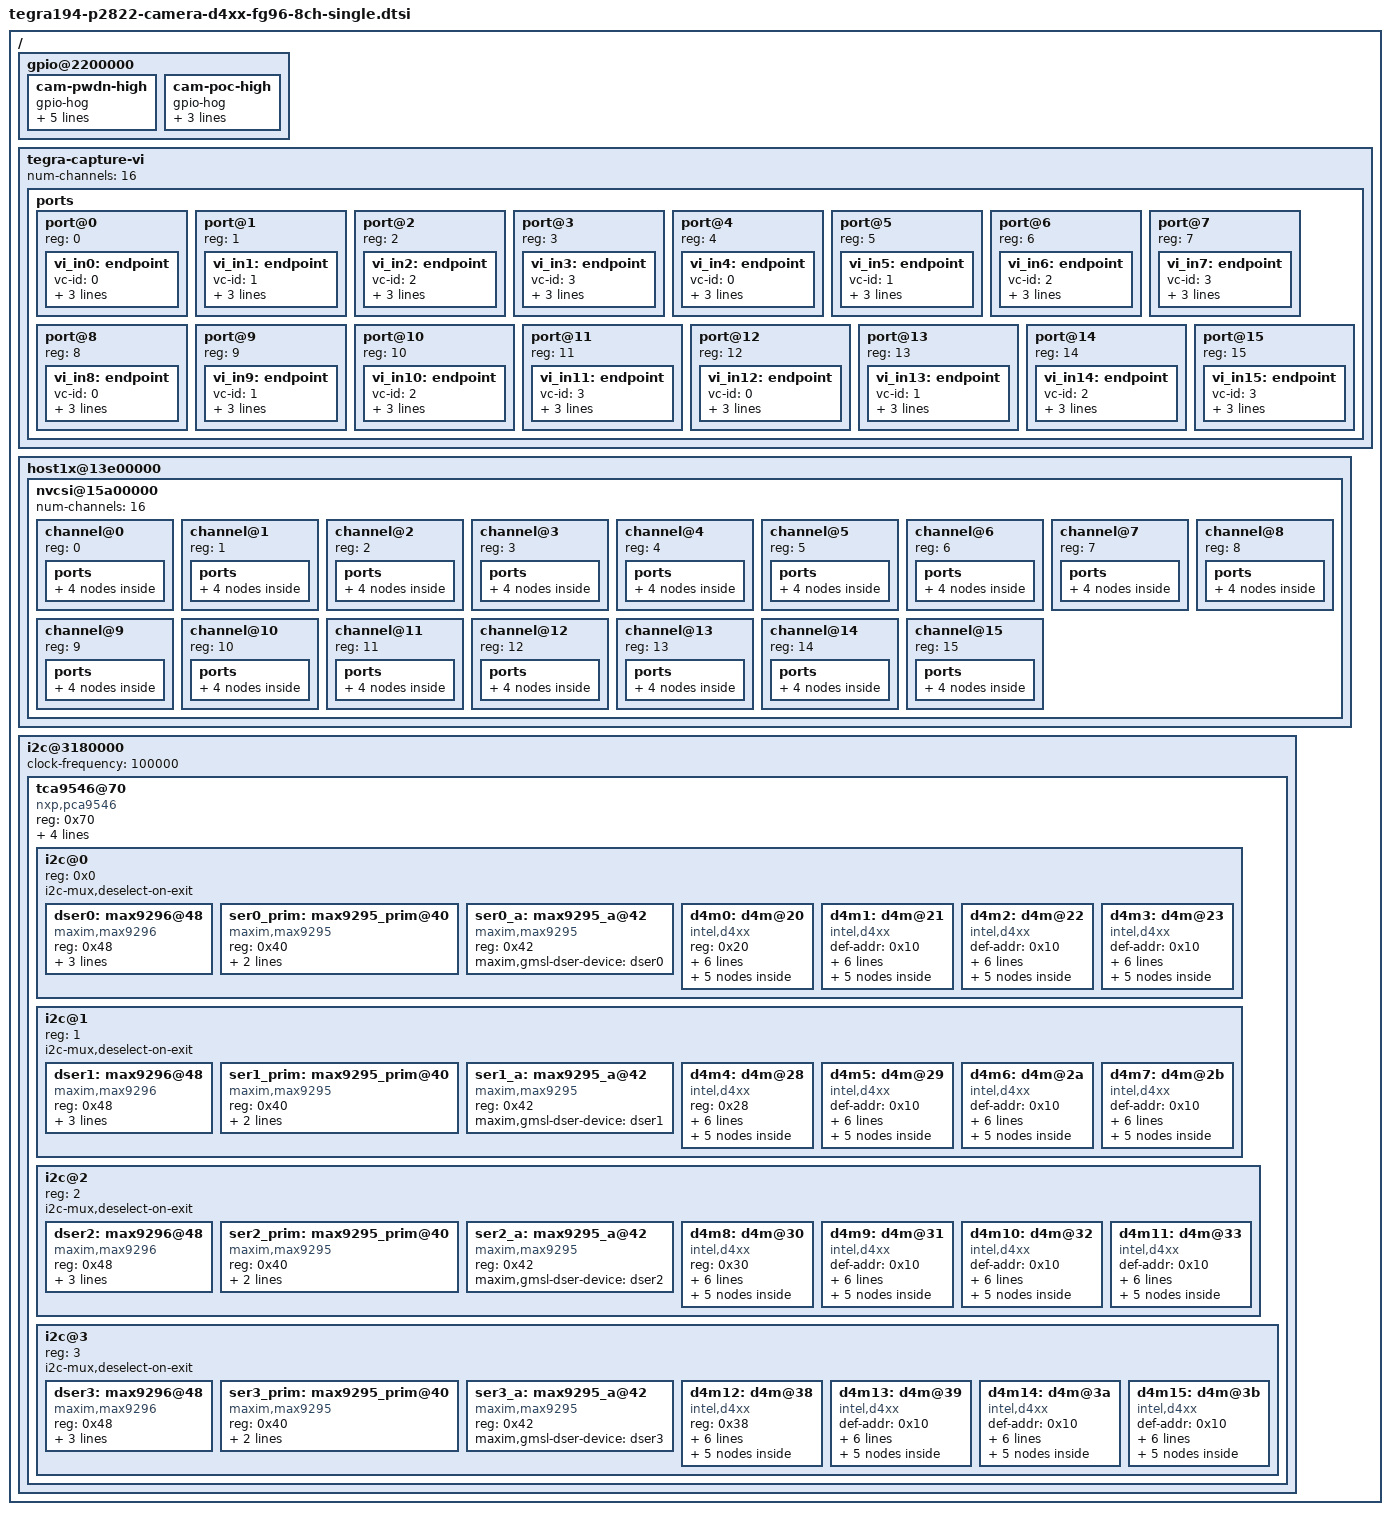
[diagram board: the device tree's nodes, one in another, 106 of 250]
// URL: https://fg96-8ch-doc.readthedocs.io/

#include "dt-bindings/clock/tegra194-clock.h"

#define CAM0_PWDN TEGRA194_MAIN_GPIO(H, 6)
#define CAM1_PWDN TEGRA194_MAIN_GPIO(H, 3)
#define CAM2_PWDN TEGRA194_MAIN_GPIO(T, 5)
#define CAM3_PWDN TEGRA194_MAIN_GPIO(T, 6)

#define CAM12V_POC TEGRA194_MAIN_GPIO(M, 5)

#define CAMERA_I2C_MUX_BUS(x) (0x1E + x)

// d4m addr 0x001cclss
// cc: max9296 index.  [0-3] for fg96
// l : a/b link index. [0-1] for a/b
// ss: stream index.   [0-3] for stream. 0: depth 1: color 2: ir 3: imu
// 4x max9296 - 4x d457
// [0x20-0x23][0x28-0x2b][0x30-0x33][0x38-0x3b]
// 4x max9296 - 8x d457
// [0x20-0x23][0x24-0x27]
// [0x28-0x2b][0x2c-0x2f]
// [0x30-0x33][0x34-0x37]
// [0x38-0x3b][0x3c-0x3f]

/ {
	gpio@2200000 {
		cam-pwdn-high {
			gpio-hog;
			output-high;
			gpios = <CAM0_PWDN 0 CAM1_PWDN 0
				 CAM2_PWDN 0 CAM3_PWDN 0>;
			label = "cam0-pwdn", "cam1-pwdn",
				"cam2-pwdn", "cam3-pwdn";
		};
		cam-poc-high {
			gpio-hog;
			output-high;
			gpios = <CAM12V_POC 0>;
			label = "cam12-poc";
		};
	};

	tegra-capture-vi {
		num-channels = <16>;

		ports {
			#address-cells = <1>;
			#size-cells = <0>;

			port@0 {
				reg = <0>;
				status = "okay";

				vi_in0: endpoint {
					status = "okay";
					vc-id = <0>;
					port-index = <0>;
					bus-width = <2>;
					remote-endpoint = <&csi_out0>;
				};
			};
			port@1 {
				reg = <1>;
				status = "okay";

				vi_in1: endpoint {
					status = "okay";
					vc-id = <1>;
					port-index = <0>;
					bus-width = <2>;
					remote-endpoint = <&csi_out1>;
				};
			};
			port@2 {
				reg = <2>;
				status = "okay";

				vi_in2: endpoint {
					status = "okay";
					vc-id = <2>;
					port-index = <0>;
					bus-width = <2>;
					remote-endpoint = <&csi_out2>;
				};
			};
			port@3 {
				reg = <3>;
				status = "okay";

				vi_in3: endpoint {
					status = "okay";
					vc-id = <3>;
					port-index = <0>;
					bus-width = <2>;
					remote-endpoint = <&csi_out3>;
				};
			};
			port@4 {
				reg = <4>;
				status = "okay";

				vi_in4: endpoint {
					status = "okay";
					vc-id = <0>;
					port-index = <2>;
					bus-width = <2>;
					remote-endpoint = <&csi_out4>;
				};
			};
			port@5 {
				reg = <5>;
				status = "okay";

				vi_in5: endpoint {
					status = "okay";
					vc-id = <1>;
					port-index = <2>;
					bus-width = <2>;
					remote-endpoint = <&csi_out5>;
				};
			};
			port@6 {
				reg = <6>;
				status = "okay";

				vi_in6: endpoint {
					status = "okay";
					vc-id = <2>;
					port-index = <2>;
					bus-width = <2>;
					remote-endpoint = <&csi_out6>;
				};
			};
			port@7 {
				reg = <7>;
				status = "okay";

				vi_in7: endpoint {
					status = "okay";
					vc-id = <3>;
					port-index = <2>;
					bus-width = <2>;
					remote-endpoint = <&csi_out7>;
				};
			};
			port@8 {
				reg = <8>;
				status = "okay";

				vi_in8: endpoint {
					status = "okay";
					vc-id = <0>;
					port-index = <4>;
					bus-width = <2>;
					remote-endpoint = <&csi_out8>;
				};
			};
			port@9 {
				reg = <9>;
				status = "okay";

				vi_in9: endpoint {
					status = "okay";
					vc-id = <1>;
					port-index = <4>;
					bus-width = <2>;
					remote-endpoint = <&csi_out9>;
				};
			};
			port@10 {
				reg = <10>;
				status = "okay";

				vi_in10: endpoint {
					status = "okay";
					vc-id = <2>;
					port-index = <4>;
					bus-width = <2>;
					remote-endpoint = <&csi_out10>;
				};
			};
			port@11 {
				reg = <11>;
				status = "okay";

				vi_in11: endpoint {
					status = "okay";
					vc-id = <3>;
					port-index = <4>;
					bus-width = <2>;
					remote-endpoint = <&csi_out11>;
				};
			};
			port@12 {
				reg = <12>;
				status = "okay";

				vi_in12: endpoint {
					status = "okay";
					vc-id = <0>;
					port-index = <5>;
					bus-width = <2>;
					remote-endpoint = <&csi_out12>;
				};
			};
			port@13 {
				reg = <13>;
				status = "okay";

				vi_in13: endpoint {
					status = "okay";
					vc-id = <1>;
					port-index = <5>;
					bus-width = <2>;
					remote-endpoint = <&csi_out13>;
				};
			};
			port@14 {
				reg = <14>;
				status = "okay";

				vi_in14: endpoint {
					status = "okay";
					vc-id = <2>;
					port-index = <5>;
					bus-width = <2>;
					remote-endpoint = <&csi_out14>;
				};
			};
			port@15 {
				reg = <15>;
				status = "okay";

				vi_in15: endpoint {
					status = "okay";
					vc-id = <3>;
					port-index = <5>;
					bus-width = <2>;
					remote-endpoint = <&csi_out15>;
				};
			};
		};
	};

	host1x@13e00000 {
		nvcsi@15a00000 {
			#address-cells = <1>;
			#size-cells = <0>;

			num-channels = <16>;

			channel@0 {
				reg = <0>;
				status = "okay";

				ports {
					#address-cells = <1>;
					#size-cells = <0>;

					port@0 {
						reg = <0>;
						status = "okay";

						csi_in0: endpoint@0 {
							status = "okay";
							port-index = <0>;
							bus-width = <2>;
							remote-endpoint = <&d4m0_out>;
						};
					};
					port@1 {
						reg = <1>;
						status = "okay";
						csi_out0: endpoint@1 {
							status = "okay";
							remote-endpoint = <&vi_in0>;
						};
					};
				};
			};
			channel@1 {
				reg = <1>;
				status = "okay";

				ports {
					#address-cells = <1>;
					#size-cells = <0>;

					port@0 {
						reg = <0>;
						status = "okay";

						csi_in1: endpoint@2 {
							status = "okay";
							port-index = <0>;
							bus-width = <2>;
							remote-endpoint = <&d4m1_out>;
						};
					};
					port@1 {
						reg = <1>;
						status = "okay";
						csi_out1: endpoint@3 {
							status = "okay";
							remote-endpoint = <&vi_in1>;
						};
					};
				};
			};
			channel@2 {
				reg = <2>;
				status = "okay";

				ports {
					#address-cells = <1>;
					#size-cells = <0>;

					port@0 {
						reg = <0>;
						status = "okay";

						csi_in2: endpoint@4 {
							status = "okay";
							port-index = <0>;
							bus-width = <2>;
							remote-endpoint = <&d4m2_out>;
						};
					};
					port@1 {
						reg = <1>;
						status = "okay";
						csi_out2: endpoint@5 {
							status = "okay";
							remote-endpoint = <&vi_in2>;
						};
					};
				};
			};
			channel@3 {
				reg = <3>;
				status = "okay";

				ports {
					#address-cells = <1>;
					#size-cells = <0>;

					port@0 {
						reg = <0>;
						status = "okay";

						csi_in3: endpoint@6 {
							status = "okay";
							port-index = <0>;
							bus-width = <2>;
							remote-endpoint = <&d4m3_out>;
						};
					};
					port@1 {
						reg = <1>;
						status = "okay";
						csi_out3: endpoint@7 {
							status = "okay";
							remote-endpoint = <&vi_in3>;
						};
					};
				};
			};
			channel@4 {
				reg = <4>;
				status = "okay";

				ports {
					#address-cells = <1>;
					#size-cells = <0>;

					port@0 {
						reg = <0>;
						status = "okay";

						csi_in4: endpoint@8 {
							status = "okay";
							port-index = <2>;
							bus-width = <2>;
							remote-endpoint = <&d4m4_out>;
						};
					};
					port@1 {
						reg = <1>;
						status = "okay";
						csi_out4: endpoint@9 {
							status = "okay";
							remote-endpoint = <&vi_in4>;
						};
					};
				};
			};
			channel@5 {
				reg = <5>;
				status = "okay";

				ports {
					#address-cells = <1>;
					#size-cells = <0>;

					port@0 {
						reg = <0>;
						status = "okay";

						csi_in5: endpoint@10 {
							status = "okay";
							port-index = <2>;
							bus-width = <2>;
							remote-endpoint = <&d4m5_out>;
						};
					};
					port@1 {
						reg = <1>;
						status = "okay";
						csi_out5: endpoint@11 {
							status = "okay";
							remote-endpoint = <&vi_in5>;
						};
					};
				};
			};
			channel@6 {
				reg = <6>;
				status = "okay";

				ports {
					#address-cells = <1>;
					#size-cells = <0>;

					port@0 {
						reg = <0>;
						status = "okay";

						csi_in6: endpoint@12 {
							status = "okay";
							port-index = <2>;
							bus-width = <2>;
							remote-endpoint = <&d4m6_out>;
						};
					};
					port@1 {
						reg = <1>;
						status = "okay";
						csi_out6: endpoint@13 {
							status = "okay";
							remote-endpoint = <&vi_in6>;
						};
					};
				};
			};
			channel@7 {
				reg = <7>;
				status = "okay";

				ports {
					#address-cells = <1>;
					#size-cells = <0>;

					port@0 {
						reg = <0>;
						status = "okay";

						csi_in7: endpoint@14 {
							status = "okay";
							port-index = <2>;
							bus-width = <2>;
							remote-endpoint = <&d4m7_out>;
						};
					};
					port@1 {
						reg = <1>;
						status = "okay";
						csi_out7: endpoint@15 {
							status = "okay";
							remote-endpoint = <&vi_in7>;
						};
					};
				};
			};
			channel@8 {
				reg = <8>;
				status = "okay";

				ports {
					#address-cells = <1>;
					#size-cells = <0>;

					port@0 {
						reg = <0>;
						status = "okay";

						csi_in8: endpoint@16 {
							status = "okay";
							port-index = <4>;
							bus-width = <2>;
							remote-endpoint = <&d4m8_out>;
						};
					};
					port@1 {
						reg = <1>;
						status = "okay";
						csi_out8: endpoint@17 {
							status = "okay";
							remote-endpoint = <&vi_in8>;
						};
					};
				};
			};
			channel@9 {
				reg = <9>;
				status = "okay";

				ports {
					#address-cells = <1>;
					#size-cells = <0>;

					port@0 {
						reg = <0>;
						status = "okay";

						csi_in9: endpoint@18 {
							status = "okay";
							port-index = <4>;
							bus-width = <2>;
							remote-endpoint = <&d4m9_out>;
						};
					};
					port@1 {
						reg = <1>;
						status = "okay";
						csi_out9: endpoint@19 {
							status = "okay";
							remote-endpoint = <&vi_in9>;
						};
					};
				};
			};
			channel@10 {
				reg = <10>;
				status = "okay";

				ports {
					#address-cells = <1>;
					#size-cells = <0>;

					port@0 {
						reg = <0>;
						status = "okay";

						csi_in10: endpoint@20 {
							status = "okay";
							port-index = <4>;
							bus-width = <2>;
							remote-endpoint = <&d4m10_out>;
						};
					};
					port@1 {
						reg = <1>;
						status = "okay";
						csi_out10: endpoint@21 {
							status = "okay";
							remote-endpoint = <&vi_in10>;
						};
					};
				};
			};
			channel@11 {
				reg = <11>;
				status = "okay";

				ports {
					#address-cells = <1>;
					#size-cells = <0>;

					port@0 {
						reg = <0>;
						status = "okay";

						csi_in11: endpoint@22 {
							status = "okay";
							port-index = <4>;
							bus-width = <2>;
							remote-endpoint = <&d4m11_out>;
						};
					};
					port@1 {
						reg = <1>;
						status = "okay";
						csi_out11: endpoint@23 {
							status = "okay";
							remote-endpoint = <&vi_in11>;
						};
					};
				};
			};
			channel@12 {
				reg = <12>;
				status = "okay";

				ports {
					#address-cells = <1>;
					#size-cells = <0>;

					port@0 {
						reg = <0>;
						status = "okay";

						csi_in12: endpoint@24 {
							status = "okay";
							port-index = <6>;
							bus-width = <2>;
							remote-endpoint = <&d4m12_out>;
						};
					};
					port@1 {
						reg = <1>;
						status = "okay";
						csi_out12: endpoint@25 {
							status = "okay";
							remote-endpoint = <&vi_in12>;
						};
					};
				};
			};
			channel@13 {
				reg = <13>;
				status = "okay";

				ports {
					#address-cells = <1>;
					#size-cells = <0>;

					port@0 {
						reg = <0>;
						status = "okay";

						csi_in13: endpoint@26 {
							status = "okay";
							port-index = <6>;
							bus-width = <2>;
							remote-endpoint = <&d4m13_out>;
						};
					};
					port@1 {
						reg = <1>;
						status = "okay";
						csi_out13: endpoint@27 {
							status = "okay";
							remote-endpoint = <&vi_in13>;
						};
					};
				};
			};
			channel@14 {
				reg = <14>;
				status = "okay";

				ports {
					#address-cells = <1>;
					#size-cells = <0>;

					port@0 {
						reg = <0>;
						status = "okay";

						csi_in14: endpoint@28 {
							status = "okay";
							port-index = <6>;
							bus-width = <2>;
							remote-endpoint = <&d4m14_out>;
						};
					};
					port@1 {
						reg = <1>;
						status = "okay";
						csi_out14: endpoint@29 {
							status = "okay";
							remote-endpoint = <&vi_in14>;
						};
					};
				};
			};
			channel@15 {
				reg = <15>;
				status = "okay";

				ports {
					#address-cells = <1>;
					#size-cells = <0>;

					port@0 {
						reg = <0>;
						status = "okay";

						csi_in15: endpoint@30 {
							status = "okay";
							port-index = <6>;
							bus-width = <2>;
							remote-endpoint = <&d4m15_out>;
						};
					};
					port@1 {
						reg = <1>;
						status = "okay";
						csi_out15: endpoint@31 {
							status = "okay";
							remote-endpoint = <&vi_in15>;
						};
					};
				};
			};
		};
	};
	i2c@3180000 {
		status = "okay";
		clock-frequency = <100000>;
		tca9546@70 {
			status = "okay";
			reg = <0x70>;
			compatible = "nxp,pca9546";
			#address-cells = <1>;
			#size-cells = <0>;
			skip_mux_detect = "yes";
			vcc-supply = <&p2822_vdd_1v8_cvb>;
			/*vcc-pullup-supply = <&battery_reg>;*/
			force_bus_start = <CAMERA_I2C_MUX_BUS(0)>;
			vcc_lp = "vcc";
			i2c@0 {
				reg = <0x0>;
				i2c-mux,deselect-on-exit;
				#address-cells = <1>;
				#size-cells = <0>;

				dser0: max9296@48 {
					status = "okay";
					reg = <0x48>;
					compatible = "maxim,max9296";
					csi-mode = "2x4";
					max-src = <1>;
					reset-gpios = <&tegra_main_gpio CAM0_PWDN GPIO_ACTIVE_HIGH>;
				};

				ser0_prim: max9295_prim@40 {
					status = "okay";
					reg = <0x40>;
					compatible = "maxim,max9295";
					is-prim-ser;
					ser-mux = <0>;
				};

				ser0_a: max9295_a@42 {
					reg = <0x42>;
					compatible = "maxim,max9295";
					maxim,gmsl-dser-device = <&dser0>;
				};

				d4m0: d4m@20 {
					status = "okay";
					reg = <0x20>;
					compatible = "intel,d4xx";
					def-addr = <0x10>;
					vcc-supply = <&p2822_vdd_1v8_cvb>;
					cam-type = "Depth";
					maxim,gmsl-ser-device = <&ser0_a>;
					maxim,gmsl-dser-device = <&dser0>;
					intel,d4m-mux-device = <&d4m3>;
					ports {
						#address-cells = <1>;
						#size-cells = <0>;

						port@0 {
							reg = <0>;
							d4m0_out: endpoint {
								port-index = <0>;
								bus-width = <2>;
								vc-id = <0>;
								remote-endpoint = <&csi_in0>;
							};
						};
					};
					mode0 {
						pixel_t = "grey_y16";
						num_lanes = "2";
						csi_pixel_bit_depth = "16";
						active_w = "1280";
						active_h = "720";
						tegra_sinterface = "serial_a";
						mclk_khz = "24000";
						pix_clk_hz = "74250000";
						line_length = "1280"; /* 2200 */
						embedded_metadata_height = "1";
					};
					gmsl-link {
						src-csi-port = "b";
						dst-csi-port = "a";
						serdes-csi-link = "a";
						csi-mode = "1x4";
						st-vc = <0>;
						vc-id = <0>;
						num-lanes = <2>;
						ser-mux = <0>;
					};
				};

				d4m1: d4m@21 {
					status = "okay";
					def-addr = <0x10>;
					reg = <0x21>;
					compatible = "intel,d4xx";
					vcc-supply = <&p2822_vdd_1v8_cvb>;
					cam-type = "RGB";
					maxim,gmsl-ser-device = <&ser0_a>;
					maxim,gmsl-dser-device = <&dser0>;
					intel,d4m-mux-device = <&d4m3>;
					ports {
						#address-cells = <1>;
						#size-cells = <0>;

						port@0 {
							reg = <0>;
							d4m1_out: endpoint {
								port-index = <0>;
								bus-width = <2>;
								vc-id = <1>;
								remote-endpoint = <&csi_in1>;
							};
						};
					};
					mode0 {
						pixel_t = "grey_y16";
						num_lanes = "2";
						csi_pixel_bit_depth = "16";
						active_w = "1920";
						active_h = "1080";
						tegra_sinterface = "serial_a";
						mclk_khz = "24000";
						pix_clk_hz = "74250000";
						line_length = "1280"; /* 2200 */
						embedded_metadata_height = "1";
					};
					gmsl-link {
						src-csi-port = "b";
						dst-csi-port = "a";
						serdes-csi-link = "a";
						csi-mode = "1x4";
						st-vc = <0>;
						vc-id = <1>;
						num-lanes = <2>;
						ser-mux = <0>;
					};
				};

				d4m2: d4m@22 {
					status = "okay";
					def-addr = <0x10>;
					reg = <0x22>;
					compatible = "intel,d4xx";
					vcc-supply = <&p2822_vdd_1v8_cvb>;
					cam-type = "Y8";
					maxim,gmsl-ser-device = <&ser0_a>;
					maxim,gmsl-dser-device = <&dser0>;
					intel,d4m-mux-device = <&d4m3>;
					ports {
						#address-cells = <1>;
						#size-cells = <0>;

						port@0 {
							reg = <0>;
							d4m2_out: endpoint {
								port-index = <0>;
								bus-width = <2>;
								vc-id = <2>;
								remote-endpoint = <&csi_in2>;
							};
						};
					};
					/* mode0: Y8, mode1: depth D16 */
					mode0 {
						pixel_t = "grey_y16";
						num_lanes = "2";
						csi_pixel_bit_depth = "16";
						active_w = "1280";
						active_h = "720";
						tegra_sinterface = "serial_a";
						mclk_khz = "24000";
						pix_clk_hz = "74250000";
						line_length = "1280"; /* 2200 */
						embedded_metadata_height = "0";
					};
					gmsl-link {
						src-csi-port = "b";
						dst-csi-port = "a";
						serdes-csi-link = "a";
						csi-mode = "1x4";
						st-vc = <0>;
						vc-id = <2>;
						num-lanes = <2>;
						ser-mux = <0>;
					};
				};

				d4m3: d4m@23 {
					status = "okay";
					def-addr = <0x10>;
					reg = <0x23>;
					compatible = "intel,d4xx";
					vcc-supply = <&p2822_vdd_1v8_cvb>;
					cam-type = "IMU";
					maxim,gmsl-ser-device = <&ser0_a>;
					maxim,gmsl-dser-device = <&dser0>;
					intel,d4m-mux-device = <&d4m3>;
					ports {
						#address-cells = <1>;
						#size-cells = <0>;

						port@0 {
							reg = <0>;
							d4m3_out: endpoint {
								port-index = <0>;
								bus-width = <2>;
								vc-id = <3>;
								remote-endpoint = <&csi_in3>;
							};
						};
					};
					mode0 {
						pixel_t = "grey_y16";
						num_lanes = "2";
						csi_pixel_bit_depth = "16";
						active_w = "640";
						active_h = "480";
						tegra_sinterface = "serial_a";
						mclk_khz = "24000";
						pix_clk_hz = "74250000";
						line_length = "1280"; /* 2200 */
						embedded_metadata_height = "0";
					};
					gmsl-link {
						src-csi-port = "b";
						dst-csi-port = "a";
						serdes-csi-link = "a";
						csi-mode = "1x4";
						st-vc = <0>;
						vc-id = <3>;
						num-lanes = <2>;
						ser-mux = <0>;
					};
				};
			};
			i2c@1 {
				reg = <1>;
				i2c-mux,deselect-on-exit;
				#address-cells = <1>;
				#size-cells = <0>;

				dser1: max9296@48 {
					status = "okay";
					reg = <0x48>;
					compatible = "maxim,max9296";
					csi-mode = "2x4";
					max-src = <1>;
					reset-gpios = <&tegra_main_gpio CAM1_PWDN GPIO_ACTIVE_HIGH>;
				};

				ser1_prim: max9295_prim@40 {
					status = "okay";
					reg = <0x40>;
					compatible = "maxim,max9295";
					is-prim-ser;
					ser-mux = <1>;
				};

				ser1_a: max9295_a@42 {
					reg = <0x42>;
					compatible = "maxim,max9295";
					maxim,gmsl-dser-device = <&dser1>;
				};

				d4m4: d4m@28 {
					status = "okay";
					reg = <0x28>;
					compatible = "intel,d4xx";
					def-addr = <0x10>;
					vcc-supply = <&p2822_vdd_1v8_cvb>;
					cam-type = "Depth";
					maxim,gmsl-ser-device = <&ser1_a>;
					maxim,gmsl-dser-device = <&dser1>;
					intel,d4m-mux-device = <&d4m7>;
					ports {
						#address-cells = <1>;
						#size-cells = <0>;

						port@0 {
							reg = <0>;
							d4m4_out: endpoint {
								port-index = <2>;
								bus-width = <2>;
								vc-id = <0>;
								remote-endpoint = <&csi_in4>;
							};
						};
					};
					mode0 {
						pixel_t = "grey_y16";
						num_lanes = "2";
						csi_pixel_bit_depth = "16";
						active_w = "1280";
						active_h = "720";
						tegra_sinterface = "serial_c";
						mclk_khz = "24000";
						pix_clk_hz = "74250000";
						line_length = "1280"; /* 2200 */
						embedded_metadata_height = "1";
					};
					gmsl-link {
						src-csi-port = "b";
						dst-csi-port = "a";
						serdes-csi-link = "a";
						csi-mode = "1x4";
						st-vc = <0>;
						vc-id = <0>;
						num-lanes = <2>;
						ser-mux = <1>;
					};
				};

				d4m5: d4m@29 {
					status = "okay";
					def-addr = <0x10>;
					reg = <0x29>;
					compatible = "intel,d4xx";
					vcc-supply = <&p2822_vdd_1v8_cvb>;
					cam-type = "RGB";
					maxim,gmsl-ser-device = <&ser1_a>;
					maxim,gmsl-dser-device = <&dser1>;
					intel,d4m-mux-device = <&d4m7>;
					ports {
						#address-cells = <1>;
						#size-cells = <0>;

						port@0 {
							reg = <0>;
							d4m5_out: endpoint {
								port-index = <2>;
								bus-width = <2>;
								vc-id = <1>;
								remote-endpoint = <&csi_in5>;
							};
						};
					};
					mode0 {
						pixel_t = "grey_y16";
						num_lanes = "2";
						csi_pixel_bit_depth = "16";
						active_w = "1920";
						active_h = "1080";
						tegra_sinterface = "serial_c";
						mclk_khz = "24000";
						pix_clk_hz = "74250000";
						line_length = "1280"; /* 2200 */
						embedded_metadata_height = "1";
					};
					gmsl-link {
						src-csi-port = "b";
						dst-csi-port = "a";
						serdes-csi-link = "a";
						csi-mode = "1x4";
						st-vc = <0>;
						vc-id = <1>;
						num-lanes = <2>;
						ser-mux = <1>;
					};
				};

				d4m6: d4m@2a {
					status = "okay";
					def-addr = <0x10>;
					reg = <0x2a>;
					compatible = "intel,d4xx";
					vcc-supply = <&p2822_vdd_1v8_cvb>;
					cam-type = "Y8";
					maxim,gmsl-ser-device = <&ser1_a>;
					maxim,gmsl-dser-device = <&dser1>;
					intel,d4m-mux-device = <&d4m7>;
					ports {
						#address-cells = <1>;
						#size-cells = <0>;

						port@0 {
							reg = <0>;
							d4m6_out: endpoint {
								port-index = <2>;
								bus-width = <2>;
								vc-id = <2>;
								remote-endpoint = <&csi_in6>;
							};
						};
					};
					/* mode0: Y8, mode1: depth D16 */
					mode0 {
						pixel_t = "grey_y16";
						num_lanes = "2";
						csi_pixel_bit_depth = "16";
						active_w = "1280";
						active_h = "720";
						tegra_sinterface = "serial_c";
						mclk_khz = "24000";
						pix_clk_hz = "74250000";
						line_length = "1280"; /* 2200 */
						embedded_metadata_height = "0";
					};
					gmsl-link {
						src-csi-port = "b";
						dst-csi-port = "a";
						serdes-csi-link = "a";
						csi-mode = "1x4";
						st-vc = <0>;
						vc-id = <2>;
						num-lanes = <2>;
						ser-mux = <1>;
					};
				};

				d4m7: d4m@2b {
					status = "okay";
					def-addr = <0x10>;
					reg = <0x2b>;
					compatible = "intel,d4xx";
					vcc-supply = <&p2822_vdd_1v8_cvb>;
					cam-type = "IMU";
					maxim,gmsl-ser-device = <&ser1_a>;
					maxim,gmsl-dser-device = <&dser1>;
					intel,d4m-mux-device = <&d4m7>;
					ports {
						#address-cells = <1>;
						#size-cells = <0>;

						port@0 {
							reg = <0>;
							d4m7_out: endpoint {
								port-index = <2>;
								bus-width = <2>;
								vc-id = <3>;
								remote-endpoint = <&csi_in7>;
							};
						};
					};
					mode0 {
						pixel_t = "grey_y16";
						num_lanes = "2";
						csi_pixel_bit_depth = "16";
						active_w = "640";
						active_h = "480";
						tegra_sinterface = "serial_c";
						mclk_khz = "24000";
						pix_clk_hz = "74250000";
						line_length = "1280"; /* 2200 */
						embedded_metadata_height = "0";
					};
					gmsl-link {
						src-csi-port = "b";
						dst-csi-port = "a";
						serdes-csi-link = "a";
						csi-mode = "1x4";
						st-vc = <0>;
						vc-id = <3>;
						num-lanes = <2>;
						ser-mux = <1>;
					};
				};
			};
			i2c@2 {
				reg = <2>;
				i2c-mux,deselect-on-exit;
				#address-cells = <1>;
				#size-cells = <0>;

				dser2: max9296@48 {
					status = "okay";
					reg = <0x48>;
					compatible = "maxim,max9296";
					csi-mode = "2x4";
					max-src = <1>;
					reset-gpios = <&tegra_main_gpio CAM2_PWDN GPIO_ACTIVE_HIGH>;
				};

				ser2_prim: max9295_prim@40 {
					status = "okay";
					reg = <0x40>;
					compatible = "maxim,max9295";
					is-prim-ser;
					ser-mux = <2>;
				};

				ser2_a: max9295_a@42 {
					reg = <0x42>;
					compatible = "maxim,max9295";
					maxim,gmsl-dser-device = <&dser2>;
				};

				d4m8: d4m@30 {
					status = "okay";
					reg = <0x30>;
					compatible = "intel,d4xx";
					def-addr = <0x10>;
					vcc-supply = <&p2822_vdd_1v8_cvb>;
					cam-type = "Depth";
					maxim,gmsl-ser-device = <&ser2_a>;
					maxim,gmsl-dser-device = <&dser2>;
					intel,d4m-mux-device = <&d4m11>;
					ports {
						#address-cells = <1>;
						#size-cells = <0>;

						port@0 {
							reg = <0>;
							d4m8_out: endpoint {
								port-index = <4>;
								bus-width = <2>;
								vc-id = <0>;
								remote-endpoint = <&csi_in8>;
							};
						};
					};
					mode0 {
						pixel_t = "grey_y16";
						num_lanes = "2";
						csi_pixel_bit_depth = "16";
						active_w = "1280";
						active_h = "720";
						tegra_sinterface = "serial_e";
						mclk_khz = "24000";
						pix_clk_hz = "74250000";
						line_length = "1280"; /* 2200 */
						embedded_metadata_height = "1";
					};
					gmsl-link {
						src-csi-port = "b";
						dst-csi-port = "a";
						serdes-csi-link = "a";
						csi-mode = "1x4";
						st-vc = <0>;
						vc-id = <0>;
						num-lanes = <2>;
						ser-mux = <2>;
					};
				};

				d4m9: d4m@31 {
					status = "okay";
					def-addr = <0x10>;
					reg = <0x31>;
					compatible = "intel,d4xx";
					vcc-supply = <&p2822_vdd_1v8_cvb>;
					cam-type = "RGB";
					maxim,gmsl-ser-device = <&ser2_a>;
					maxim,gmsl-dser-device = <&dser2>;
					intel,d4m-mux-device = <&d4m11>;
					ports {
						#address-cells = <1>;
						#size-cells = <0>;

						port@0 {
							reg = <0>;
							d4m9_out: endpoint {
								port-index = <4>;
								bus-width = <2>;
								vc-id = <1>;
								remote-endpoint = <&csi_in9>;
							};
						};
					};
					mode0 {
						pixel_t = "grey_y16";
						num_lanes = "2";
						csi_pixel_bit_depth = "16";
						active_w = "1920";
						active_h = "1080";
						tegra_sinterface = "serial_e";
						mclk_khz = "24000";
						pix_clk_hz = "74250000";
						line_length = "1280"; /* 2200 */
						embedded_metadata_height = "1";
					};
					gmsl-link {
						src-csi-port = "b";
						dst-csi-port = "a";
						serdes-csi-link = "a";
						csi-mode = "1x4";
						st-vc = <0>;
						vc-id = <1>;
						num-lanes = <2>;
						ser-mux = <2>;
					};
				};

				d4m10: d4m@32 {
					status = "okay";
					def-addr = <0x10>;
					reg = <0x32>;
					compatible = "intel,d4xx";
					vcc-supply = <&p2822_vdd_1v8_cvb>;
					cam-type = "Y8";
					maxim,gmsl-ser-device = <&ser2_a>;
					maxim,gmsl-dser-device = <&dser2>;
					intel,d4m-mux-device = <&d4m11>;
					ports {
						#address-cells = <1>;
						#size-cells = <0>;

						port@0 {
							reg = <0>;
							d4m10_out: endpoint {
								port-index = <4>;
								bus-width = <2>;
								vc-id = <2>;
								remote-endpoint = <&csi_in10>;
							};
						};
					};
					/* mode0: Y8, mode1: depth D16 */
					mode0 {
						pixel_t = "grey_y16";
						num_lanes = "2";
						csi_pixel_bit_depth = "16";
						active_w = "1280";
						active_h = "720";
						tegra_sinterface = "serial_e";
						mclk_khz = "24000";
						pix_clk_hz = "74250000";
						line_length = "1280"; /* 2200 */
						embedded_metadata_height = "0";
					};
					gmsl-link {
						src-csi-port = "b";
						dst-csi-port = "a";
						serdes-csi-link = "a";
						csi-mode = "1x4";
						st-vc = <0>;
						vc-id = <2>;
						num-lanes = <2>;
						ser-mux = <2>;
					};
				};

				d4m11: d4m@33 {
					status = "okay";
					def-addr = <0x10>;
					reg = <0x33>;
					compatible = "intel,d4xx";
					vcc-supply = <&p2822_vdd_1v8_cvb>;
					cam-type = "IMU";
					maxim,gmsl-ser-device = <&ser2_a>;
					maxim,gmsl-dser-device = <&dser2>;
					intel,d4m-mux-device = <&d4m11>;
					ports {
						#address-cells = <1>;
						#size-cells = <0>;

						port@0 {
							reg = <0>;
							d4m11_out: endpoint {
								port-index = <4>;
								bus-width = <2>;
								vc-id = <3>;
								remote-endpoint = <&csi_in11>;
							};
						};
					};
					mode0 {
						pixel_t = "grey_y16";
						num_lanes = "2";
						csi_pixel_bit_depth = "16";
						active_w = "640";
						active_h = "480";
						tegra_sinterface = "serial_e";
						mclk_khz = "24000";
						pix_clk_hz = "74250000";
						line_length = "1280"; /* 2200 */
						embedded_metadata_height = "0";
					};
					gmsl-link {
						src-csi-port = "b";
						dst-csi-port = "a";
						serdes-csi-link = "a";
						csi-mode = "1x4";
						st-vc = <0>;
						vc-id = <3>;
						num-lanes = <2>;
						ser-mux = <2>;
					};
				};
			};
			i2c@3 {
				reg = <3>;
				i2c-mux,deselect-on-exit;
				#address-cells = <1>;
				#size-cells = <0>;

				dser3: max9296@48 {
					status = "okay";
					reg = <0x48>;
					compatible = "maxim,max9296";
					csi-mode = "2x4";
					max-src = <1>;
					reset-gpios = <&tegra_main_gpio CAM3_PWDN GPIO_ACTIVE_HIGH>;
				};

				ser3_prim: max9295_prim@40 {
					status = "okay";
					reg = <0x40>;
					compatible = "maxim,max9295";
					is-prim-ser;
					ser-mux = <3>;
				};

				ser3_a: max9295_a@42 {
					reg = <0x42>;
					compatible = "maxim,max9295";
					maxim,gmsl-dser-device = <&dser3>;
				};

				d4m12: d4m@38 {
					status = "okay";
					reg = <0x38>;
					compatible = "intel,d4xx";
					def-addr = <0x10>;
					vcc-supply = <&p2822_vdd_1v8_cvb>;
					cam-type = "Depth";
					maxim,gmsl-ser-device = <&ser3_a>;
					maxim,gmsl-dser-device = <&dser3>;
					intel,d4m-mux-device = <&d4m15>;
					ports {
						#address-cells = <1>;
						#size-cells = <0>;

						port@0 {
							reg = <0>;
							d4m12_out: endpoint {
								port-index = <5>;
								bus-width = <2>;
								vc-id = <0>;
								remote-endpoint = <&csi_in12>;
							};
						};
					};
					mode0 {
						pixel_t = "grey_y16";
						num_lanes = "2";
						csi_pixel_bit_depth = "16";
						active_w = "1280";
						active_h = "720";
						tegra_sinterface = "serial_g";
						mclk_khz = "24000";
						pix_clk_hz = "74250000";
						line_length = "1280"; /* 2200 */
						embedded_metadata_height = "1";
					};
					gmsl-link {
						src-csi-port = "b";
						dst-csi-port = "a";
						serdes-csi-link = "a";
						csi-mode = "1x4";
						st-vc = <0>;
						vc-id = <0>;
						num-lanes = <2>;
						ser-mux = <3>;
					};
				};
				d4m13: d4m@39 {
					status = "okay";
					def-addr = <0x10>;
					reg = <0x39>;
					compatible = "intel,d4xx";
					vcc-supply = <&p2822_vdd_1v8_cvb>;
					cam-type = "RGB";
					maxim,gmsl-ser-device = <&ser3_a>;
					maxim,gmsl-dser-device = <&dser3>;
					intel,d4m-mux-device = <&d4m15>;
					ports {
						#address-cells = <1>;
						#size-cells = <0>;

						port@0 {
							reg = <0>;
							d4m13_out: endpoint {
								port-index = <5>;
								bus-width = <2>;
								vc-id = <1>;
								remote-endpoint = <&csi_in13>;
							};
						};
					};
					mode0 {
						pixel_t = "grey_y16";
						num_lanes = "2";
						csi_pixel_bit_depth = "16";
						active_w = "1920";
						active_h = "1080";
						tegra_sinterface = "serial_g";
						mclk_khz = "24000";
						pix_clk_hz = "74250000";
						line_length = "1280"; /* 2200 */
						embedded_metadata_height = "1";
					};
					gmsl-link {
						src-csi-port = "b";
						dst-csi-port = "a";
						serdes-csi-link = "a";
						csi-mode = "1x4";
						st-vc = <0>;
						vc-id = <1>;
						num-lanes = <2>;
						ser-mux = <3>;
					};
				};

				d4m14: d4m@3a {
					status = "okay";
					def-addr = <0x10>;
					reg = <0x3a>;
					compatible = "intel,d4xx";
					vcc-supply = <&p2822_vdd_1v8_cvb>;
					cam-type = "Y8";
					maxim,gmsl-ser-device = <&ser3_a>;
					maxim,gmsl-dser-device = <&dser3>;
					intel,d4m-mux-device = <&d4m15>;
					ports {
						#address-cells = <1>;
						#size-cells = <0>;

						port@0 {
							reg = <0>;
							d4m14_out: endpoint {
								port-index = <5>;
								bus-width = <2>;
								vc-id = <2>;
								remote-endpoint = <&csi_in14>;
							};
						};
					};
					/* mode0: Y8, mode1: depth D16 */
					mode0 {
						pixel_t = "grey_y16";
						num_lanes = "2";
						csi_pixel_bit_depth = "16";
						active_w = "1280";
						active_h = "720";
						tegra_sinterface = "serial_g";
						mclk_khz = "24000";
						pix_clk_hz = "74250000";
						line_length = "1280"; /* 2200 */
						embedded_metadata_height = "0";
					};
					gmsl-link {
						src-csi-port = "b";
						dst-csi-port = "a";
						serdes-csi-link = "a";
						csi-mode = "1x4";
						st-vc = <0>;
						vc-id = <2>;
						num-lanes = <2>;
						ser-mux = <3>;
					};
				};

				d4m15: d4m@3b {
					status = "okay";
					def-addr = <0x10>;
					reg = <0x3b>;
					compatible = "intel,d4xx";
					vcc-supply = <&p2822_vdd_1v8_cvb>;
					cam-type = "IMU";
					maxim,gmsl-ser-device = <&ser3_a>;
					maxim,gmsl-dser-device = <&dser3>;
					intel,d4m-mux-device = <&d4m15>;
					ports {
						#address-cells = <1>;
						#size-cells = <0>;

						port@0 {
							reg = <0>;
							d4m15_out: endpoint {
								port-index = <5>;
								bus-width = <2>;
								vc-id = <3>;
								remote-endpoint = <&csi_in15>;
							};
						};
					};
					mode0 {
						pixel_t = "grey_y16";
						num_lanes = "2";
						csi_pixel_bit_depth = "16";
						active_w = "640";
						active_h = "480";
						tegra_sinterface = "serial_g";
						mclk_khz = "24000";
						pix_clk_hz = "74250000";
						line_length = "1280"; /* 2200 */
						embedded_metadata_height = "0";
					};
					gmsl-link {
						src-csi-port = "b";
						dst-csi-port = "a";
						serdes-csi-link = "a";
						csi-mode = "1x4";
						st-vc = <0>;
						vc-id = <3>;
						num-lanes = <2>;
						ser-mux = <3>;
					};
				};
			};
		};
	};
};
